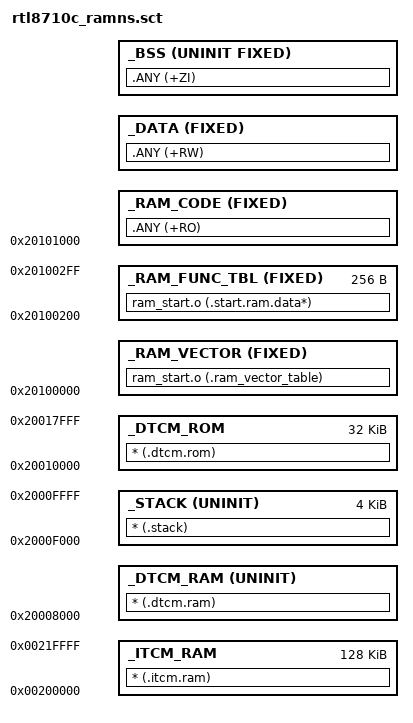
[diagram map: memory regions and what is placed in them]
; *************************************************************
; *** Scatter-Loading Description File for RTL8195BHP       ***
; *************************************************************
LR_ITCM 0x00002000 0x001FD000  {    ; load region size_region
  _ITCM_RAM 0x00200000 0x00020000  {  ; ITCM for Text & RO Data
  	* (.itcm.ram)
  }
}

LR_DTCM 0x20008000 0x00010000  {    ; load region size_region

  _DTCM_RAM 0x20008000 UNINIT {
  	* (.dtcm.ram)
  }
  
  _STACK 0x2000F000 UNINIT 0x00001000  {
  	* (.stack)
  }

  _DTCM_ROM 0x20010000 0x00008000  {  ; DTCM RO data
  	* (.dtcm.rom)
  }
}

LR_RAM 0x20100000 0x00160000  {    ; load region size_region
  _RAM_VECTOR 0x20100000 FIXED {  ; RW data
	ram_start.o (.ram_vector_table)
  }
  
  _RAM_FUNC_TBL 0x20100200 FIXED 0x100 {
    ram_start.o (.start.ram.data*)
  }

  _RAM_CODE 0x20101000 FIXED {
    .ANY (+RO)
  }
  
  _DATA +0 FIXED {
    .ANY (+RW)
  }

  _BSS +0 UNINIT FIXED {
    .ANY (+ZI)
  }
}
